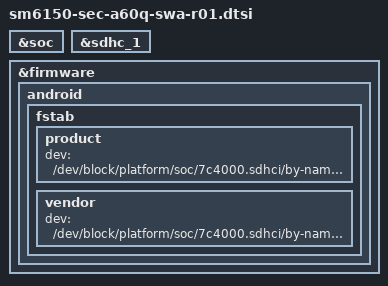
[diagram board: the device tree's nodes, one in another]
/* Copyright (c) 2018, The Linux Foundation. All rights reserved.
 *
 * This program is free software; you can redistribute it and/or modify
 * it under the terms of the GNU General Public License version 2 and
 * only version 2 as published by the Free Software Foundation.
 *
 * This program is distributed in the hope that it will be useful,
 * but WITHOUT ANY WARRANTY; without even the implied warranty of
 * MERCHANTABILITY or FITNESS FOR A PARTICULAR PURPOSE.  See the
 * GNU General Public License for more details.
 */

#include "sm6150-sec-a60q-swa-r00.dtsi"

&soc {
	/* not use ufs */
	/delete-node/ ufsphy_mem@1d87000;
	/delete-node/ ufshc@1d84000;
	/delete-node/ ufsice@1d90000;
};

/* use eMMC */
&sdhc_1 {
	status = "ok";
};

&firmware {
	android {
		fstab {
			product {
				dev = "/dev/block/platform/soc/7c4000.sdhci/by-name/product";
			};
			vendor {
				dev = "/dev/block/platform/soc/7c4000.sdhci/by-name/vendor";
			};
		};
	};
};
